CM_ "IMPORT _bosch_2018.dbc"

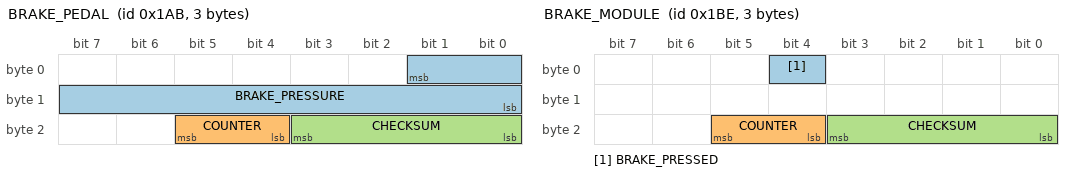
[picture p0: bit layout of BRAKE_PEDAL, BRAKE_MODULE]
BO_ 427 BRAKE_PEDAL: 3 VSA
 SG_ BRAKE_PRESSURE : 1|10@0+ (1,0) [0|255] "" XXX
 SG_ COUNTER : 21|2@0+ (1,0) [0|3] "" XXX
 SG_ CHECKSUM : 19|4@0+ (1,0) [0|15] "" XXX

BO_ 446 BRAKE_MODULE: 3 VSA
 SG_ BRAKE_PRESSED : 4|1@0+ (1,0) [0|1] "" XXX
 SG_ COUNTER : 21|2@0+ (1,0) [0|3] "" XXX
 SG_ CHECKSUM : 19|4@0+ (1,0) [0|15] "" XXX

BO_ 490 XXX_12: 8 XXX
 SG_ BOH : 7|32@0+ (1,0) [0|65535] "" XXX
 SG_ BOH_2 : 23|16@0+ (1,0) [0|65535] "" XXX
 SG_ COUNTER : 61|2@0+ (1,0) [0|3] "" XXX
 SG_ CHECKSUM : 59|4@0+ (1,0) [0|15] "" XXX

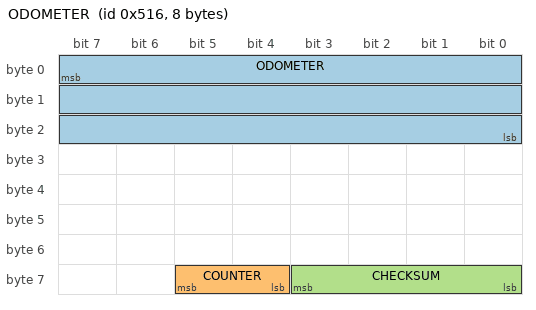
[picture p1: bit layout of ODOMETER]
BO_ 1302 ODOMETER: 8 XXX
 SG_ ODOMETER : 7|24@0+ (1,0) [0|16777215] "km" EON
 SG_ COUNTER : 61|2@0+ (1,0) [0|3] "" EON
 SG_ CHECKSUM : 59|4@0+ (1,0) [0|3] "" EON

CM_ SG_ 450 EPB_STATE "3: On, 2: Disengaging, 1: Engaging, 0: Off";
CM_ SG_ 479 CONTROL_ON "Set to 5 when car is being controlled";
CM_ SG_ 479 RELATED_TO_GAS "bits 7, 3, and 1 set to 1 when gas not applied";
CM_ SG_ 479 GAS_BRAKE "Signed value, negative when braking and positive when applying gas";

VAL_ 780 CRUISE_SPEED 255 "no_speed" 252 "stopped" ;
VAL_ 780 HUD_LEAD 3 "acc_off" 2 "solid_car" 1 "dashed_car" 0 "no_car" ;
VAL_ 806 CMBS_STATES 3 "pressed" 2 "on" 0 "off";
VAL_ 829 BEEP 3 "single_beep" 2 "triple_beep" 1 "repeated_beep" 0 "no_beep" ;

CM_ "CHFFR_METRIC 330 STEER_ANGLE STEER_ANGLE 0.36 180; CHFFR_METRIC 380 ENGINE_RPM ENGINE_RPM 1 0; CHFFR_METRIC 804 ENGINE_TEMPERATURE ENGINE_TEMPERATURE 1 0";
